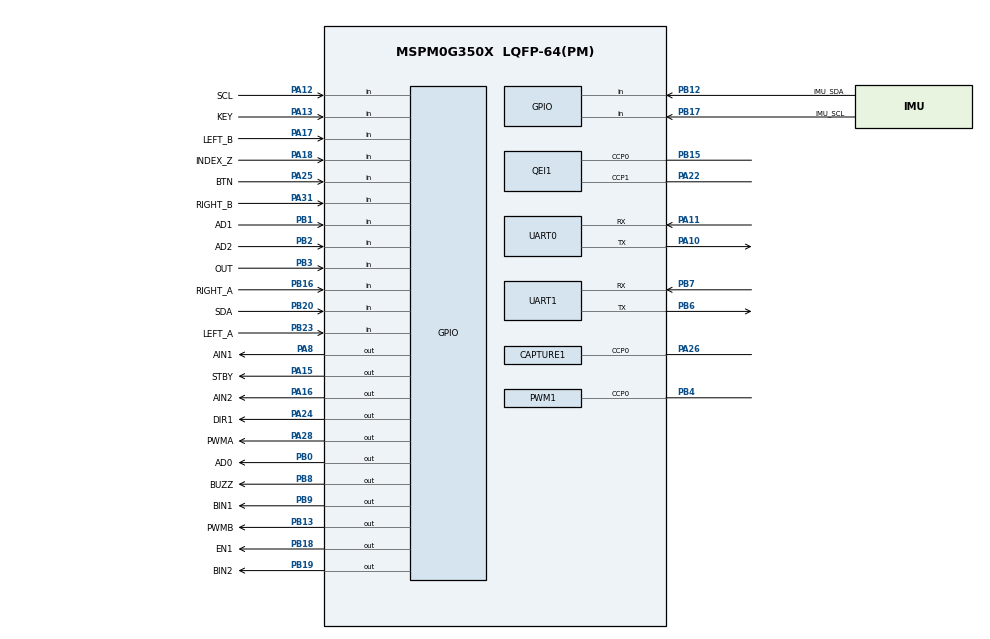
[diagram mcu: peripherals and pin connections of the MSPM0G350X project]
/**
 * @cliArgs --device "MSPM0G350X" --part "Default" --package "LQFP-64(PM)" --product "mspm0_sdk@2.10.00.04"
 * @versions {"tool":"1.27.0+4565"}
 */

/**
 * Import the modules used in this configuration.
 */
const GPIO   = scripting.addModule("/ti/driverlib/GPIO", {}, false);
const GPIO1  = GPIO.addInstance();
const GPIO2  = GPIO.addInstance();
const GPIO3  = GPIO.addInstance();
const GPIO4  = GPIO.addInstance();
const GPIO5  = GPIO.addInstance();
const GPIO6  = GPIO.addInstance();
const GPIO7  = GPIO.addInstance();
const GPIO8  = GPIO.addInstance();
const GPIO9  = GPIO.addInstance();
const GPIO10 = GPIO.addInstance();
const UART   = scripting.addModule("/ti/driverlib/UART", {}, false);
const UART0  = UART.addInstance();
const UART1  = UART.addInstance();
const SYSCTL = scripting.addModule("/ti/driverlib/SYSCTL");
const TIMER  = scripting.addModule("/ti/driverlib/TIMER", {}, false);
const TIMER1 = TIMER.addInstance();
const PWM      = scripting.addModule("/ti/driverlib/PWM", {}, false);
const PWM1     = PWM.addInstance();
const QEI      = scripting.addModule("/ti/driverlib/QEI", {}, false);
const QEI1     = QEI.addInstance();
const CAPTURE  = scripting.addModule("/ti/driverlib/CAPTURE", {}, false);
const CAPTURE1 = CAPTURE.addInstance();

/**
 * Write custom configuration values to the imported modules.
 */

const Board = scripting.addModule("/ti/driverlib/Board", {}, false);

/* MODE_KEY: PA13, input with pull-up. Firmware detects a change from the
 * power-on released level, so either external active-low/high wiring works. */
GPIO5.$name                              = "MODE_KEY";
GPIO5.port                               = "PORTA";
GPIO5.associatedPins[0].$name            = "KEY";
GPIO5.associatedPins[0].direction        = "INPUT";
GPIO5.associatedPins[0].internalResistor = "PULL_UP";
GPIO5.associatedPins[0].pin.$assign      = "PA13";

/* BUZZER: PB8, output, initial HIGH (active-low buzzer off). */
GPIO6.$name                          = "BUZZER";
GPIO6.port                           = "PORTB";
GPIO6.associatedPins[0].$name        = "BUZZ";
GPIO6.associatedPins[0].initialValue = "SET";
GPIO6.associatedPins[0].pin.$assign  = "PB8";

/* OLED software I2C: released inputs with pull-ups; firmware only drives LOW. */
GPIO7.$name                              = "OLED_I2C";
GPIO7.associatedPins.create(2);
GPIO7.associatedPins[0].$name            = "SCL";
GPIO7.associatedPins[0].direction        = "INPUT";
GPIO7.associatedPins[0].internalResistor = "PULL_UP";
GPIO7.associatedPins[0].pin.$assign      = "PA12";
GPIO7.associatedPins[1].$name            = "SDA";
GPIO7.associatedPins[1].direction        = "INPUT";
GPIO7.associatedPins[1].internalResistor = "PULL_UP";
GPIO7.associatedPins[1].pin.$assign      = "PB20";

/* IMU (ICM-42688-P) software I2C: SCL=PB17, SDA=PB12, matching the pinout of
 * the sibling ball-control firmware. Released inputs with pull-ups; the
 * firmware only ever drives a line LOW (open-drain emulation).
 * Wiring note: the module's CS must be tied HIGH to select I2C mode, and AD0
 * selects the address (LOW = 0x68, HIGH = 0x69); the driver probes both. */
GPIO8.$name                              = "IMU_I2C";
GPIO8.port                               = "PORTB";
GPIO8.associatedPins.create(2);
GPIO8.associatedPins[0].$name            = "IMU_SCL";
GPIO8.associatedPins[0].direction        = "INPUT";
GPIO8.associatedPins[0].internalResistor = "PULL_UP";
GPIO8.associatedPins[0].pin.$assign      = "PB17";
GPIO8.associatedPins[1].$name            = "IMU_SDA";
GPIO8.associatedPins[1].direction        = "INPUT";
GPIO8.associatedPins[1].internalResistor = "PULL_UP";
GPIO8.associatedPins[1].pin.$assign      = "PB12";

/* D36A pendulum stepper control lines. Both start CLEARED: EN is active-high
 * in stepper.c (STEPPER_EN_ACTIVE_HIGH), so the driver is disabled at reset
 * and the rod cannot move before firmware asks for it. */
GPIO9.$name                          = "STEPPER_CTRL";
GPIO9.associatedPins.create(2);
GPIO9.associatedPins[0].$name        = "DIR1";
GPIO9.associatedPins[0].initialValue = "CLEARED";
GPIO9.associatedPins[0].pin.$assign  = "PA24";
GPIO9.associatedPins[1].$name        = "EN1";
GPIO9.associatedPins[1].initialValue = "CLEARED";
GPIO9.associatedPins[1].pin.$assign  = "PB18";

/* Stepper encoder Z index: rising-edge GPIO interrupt on PA18. Lands in the
 * same GROUP1 vector as the wheel encoders (which are on GPIOB), so
 * GROUP1_IRQHandler() in chassis_iface.c must dispatch to both. */
GPIO10.$name                         = "STEPPER_ENCODER";
GPIO10.port                          = "PORTA";
GPIO10.associatedPins[0].$name       = "INDEX_Z";
GPIO10.associatedPins[0].direction   = "INPUT";
GPIO10.associatedPins[0].interruptEn = true;
GPIO10.associatedPins[0].polarity    = "RISE";
GPIO10.associatedPins[0].pin.$assign = "PA18";

/* Stepper encoder A/B quadrature on TIMG8. */
QEI1.$name                      = "STEPPER_QEI";
QEI1.peripheral.$assign         = "TIMG8";
QEI1.peripheral.ccp0Pin.$assign = "PB15";
QEI1.peripheral.ccp1Pin.$assign = "PA22";

/* PA26 absolute-angle PWM, combined capture on TIMG7 at 1 MHz. The 65.536 ms
 * period bounds one capture window; a ZERO event means the signal went away
 * and invalidates the reading. */
CAPTURE1.$name                      = "STEPPER_ABS_PWM";
CAPTURE1.ccIndex                    = 0;
CAPTURE1.captMode                   = "COMBINED";
CAPTURE1.timerClkPrescale           = 32;
CAPTURE1.timerPeriod                = "65.536 ms";
CAPTURE1.interrupts                 = ["CC1_DN","ZERO"];
CAPTURE1.peripheral.$assign         = "TIMG7";
CAPTURE1.peripheral.ccp0Pin.$assign = "PA26";

/* D36A STEP output: PB4/TIMA1_CCP0, 1 MHz timer clock. The 200 Hz initial
 * waveform is only a placeholder -- stepper_set_speed() rewrites load and
 * compare on every command. CC0_DN drives the pulse counter that makes
 * stepper_jog() finite. */
PWM1.$name                          = "STEPPER_PWM";
PWM1.ccIndex                        = [0];
PWM1.clockPrescale                  = 32;
PWM1.timerCount                     = 4999;
PWM1.enableShadowLoad               = true;
PWM1.interrupts                     = ["CC0_DN_EVENT"];
PWM1.peripheral.$assign             = "TIMA1";
PWM1.peripheral.ccp0Pin.$assign     = "PB4";
PWM1.PWM_CHANNEL_0.$name            = "STEPPER_STEP";
PWM1.PWM_CHANNEL_0.ccValue          = 2499;
PWM1.PWM_CHANNEL_0.shadowUpdateMode = "ZERO_EVT";

/* START_KEY: PA25, input, pull-up, active-low. Currently not used by auto-run firmware. */
GPIO1.$name                              = "START_KEY";
GPIO1.port                               = "PORTA";
GPIO1.associatedPins[0].$name            = "BTN";
GPIO1.associatedPins[0].direction        = "INPUT";
GPIO1.associatedPins[0].internalResistor = "PULL_UP";
GPIO1.associatedPins[0].pin.$assign      = "PA25";

/* GRAY_SENSOR: 8-ch red-light module, AD0=PB0, AD1=PB1, AD2=PB2, OUT=PB3 */
GPIO2.$name                         = "GRAY_SENSOR";
GPIO2.port                          = "PORTB";
GPIO2.associatedPins.create(4);
GPIO2.associatedPins[0].$name       = "AD0";
GPIO2.associatedPins[0].pin.$assign = "PB0";
  GPIO2.associatedPins[1].$name       = "AD1";
  GPIO2.associatedPins[1].direction   = "INPUT";
  GPIO2.associatedPins[1].internalResistor = "PULL_UP";
  GPIO2.associatedPins[1].pin.$assign = "PB1";
  GPIO2.associatedPins[2].$name       = "AD2";
  GPIO2.associatedPins[2].direction   = "INPUT";
  GPIO2.associatedPins[2].internalResistor = "PULL_UP";
  GPIO2.associatedPins[2].pin.$assign = "PB2";
GPIO2.associatedPins[3].$name       = "OUT";
GPIO2.associatedPins[3].direction   = "INPUT";
GPIO2.associatedPins[3].internalResistor = "PULL_UP";
GPIO2.associatedPins[3].pin.$assign = "PB3";

/* GPIO_MOTOR: TB6612 2-ch motor driver, 7 output pins */
GPIO3.$name                         = "GPIO_MOTOR";
GPIO3.associatedPins.create(7);
GPIO3.associatedPins[0].$name       = "AIN1";
GPIO3.associatedPins[0].pin.$assign = "PA8";
GPIO3.associatedPins[1].$name       = "AIN2";
GPIO3.associatedPins[1].pin.$assign = "PA16";
GPIO3.associatedPins[2].$name       = "BIN1";
GPIO3.associatedPins[2].pin.$assign = "PB9";
GPIO3.associatedPins[3].$name       = "BIN2";
GPIO3.associatedPins[3].pin.$assign = "PB19";
GPIO3.associatedPins[4].$name       = "STBY";
GPIO3.associatedPins[4].pin.$assign = "PA15";
GPIO3.associatedPins[5].$name       = "PWMA";
GPIO3.associatedPins[5].pin.$assign = "PA28";
GPIO3.associatedPins[6].$name       = "PWMB";
GPIO3.associatedPins[6].pin.$assign = "PB13";

/* GPIO_ENCODER: 2 wheels x A/B */
GPIO4.$name = "GPIO_ENCODER";
GPIO4.associatedPins.create(4);
GPIO4.associatedPins[0].$name = "LEFT_A";
GPIO4.associatedPins[0].direction = "INPUT";
GPIO4.associatedPins[0].internalResistor = "PULL_UP";
GPIO4.associatedPins[0].interruptEn = true;
GPIO4.associatedPins[0].polarity = "RISE_FALL";
GPIO4.associatedPins[0].pin.$assign = "PB23";
GPIO4.associatedPins[1].$name = "LEFT_B";
GPIO4.associatedPins[1].direction = "INPUT";
GPIO4.associatedPins[1].internalResistor = "PULL_UP";
GPIO4.associatedPins[1].pin.$assign = "PA17";
GPIO4.associatedPins[2].$name = "RIGHT_A";
GPIO4.associatedPins[2].direction = "INPUT";
GPIO4.associatedPins[2].internalResistor = "PULL_UP";
GPIO4.associatedPins[2].interruptEn = true;
GPIO4.associatedPins[2].polarity = "RISE_FALL";
GPIO4.associatedPins[2].pin.$assign = "PB16";
GPIO4.associatedPins[3].$name = "RIGHT_B";
GPIO4.associatedPins[3].direction = "INPUT";
GPIO4.associatedPins[3].internalResistor = "PULL_UP";
GPIO4.associatedPins[3].pin.$assign = "PA31";

/* DEBUG_UART / LoRa: UART0, PA10=TX, PA11=RX, 115200 baud */
UART0.$name                    = "DEBUG_UART";
UART0.targetBaudRate           = 115200;
UART0.peripheral.$assign       = "UART0";
UART0.peripheral.txPin.$assign = "PA10";
UART0.peripheral.rxPin.$assign = "PA11";

/* VISION_UART: UART1, PB6=TX, PB7=RX, 115200 baud.
 * Raised from 9600: the ball telemetry line
 *   timestamp=..,valid=..,position_mm=..,velocity_mm_s=..,x=..,y=..,recording=..
 * runs 80-100 bytes, which needs ~90 ms per line at 9600 baud -- barely 10 Hz,
 * and close enough to VISION_TELEMETRY_TIMEOUT_MS (250) that a couple of
 * retransmits would drop the link. At 115200 a line takes ~8 ms. The vision
 * sender must be set to 115200 to match. */
UART1.$name                    = "VISION_UART";
UART1.targetBaudRate           = 115200;
UART1.peripheral.$assign       = "UART1";
UART1.peripheral.txPin.$assign = "PB6";
UART1.peripheral.rxPin.$assign = "PB7";

/* Independent 1 ms timebase for the optional OLED stopwatch mode. */
TIMER1.$name              = "STOPWATCH_TIMER";
TIMER1.timerPeriod        = "1 ms";
TIMER1.timerMode          = "PERIODIC";
TIMER1.interrupts         = ["ZERO"];
TIMER1.timerClkPrescale   = 1;
TIMER1.peripheral.$assign = "TIMG12";

SYSCTL.forceDefaultClkConfig = true;
SYSCTL.clockTreeEn           = true;

/**
 * Pinmux solution for unlocked pins/peripherals. This ensures that minor changes to the automatic solver in a future
 * version of the tool will not impact the pinmux you originally saw. These lines can be deleted to re-solve from scratch.
 */
Board.peripheral.$suggestSolution          = "DEBUGSS";
Board.peripheral.swclkPin.$suggestSolution = "PA20";
Board.peripheral.swdioPin.$suggestSolution = "PA19";
